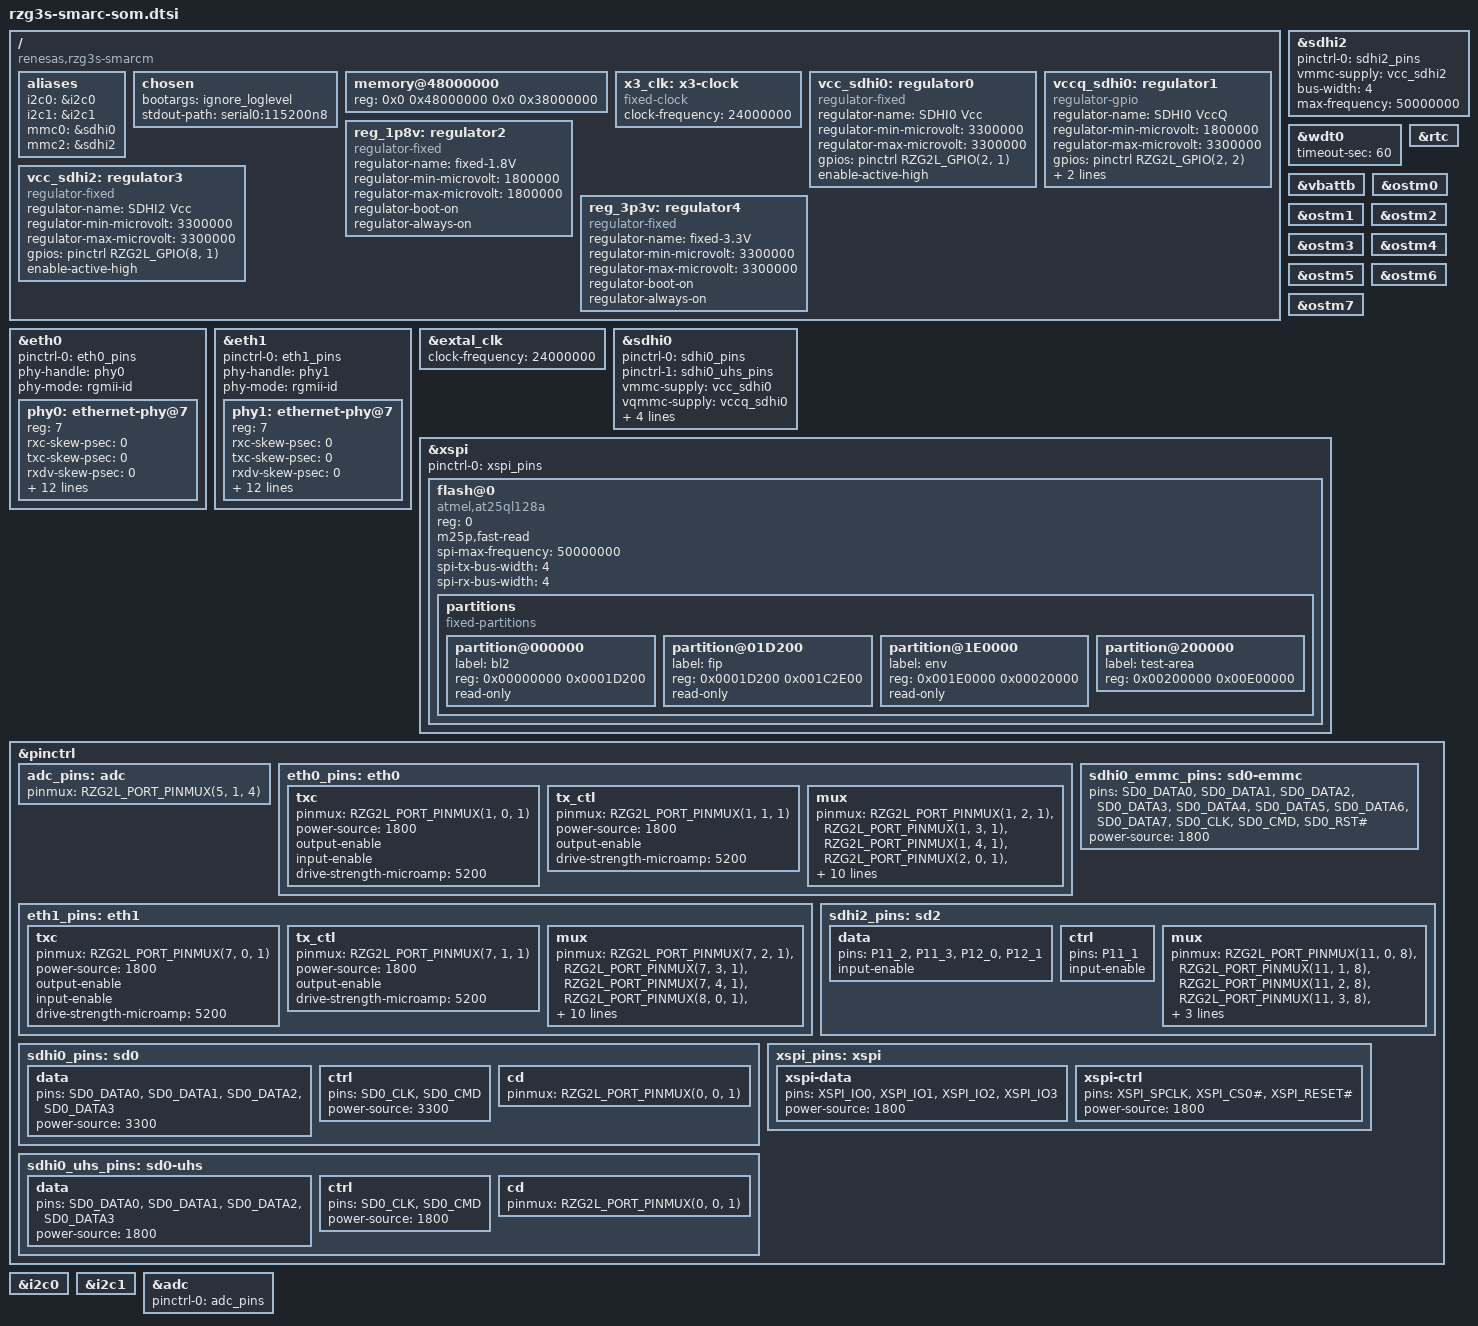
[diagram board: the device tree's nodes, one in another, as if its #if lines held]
// SPDX-License-Identifier: (GPL-2.0-only OR BSD-2-Clause)
/*
 * Device Tree Source for the R9A08G045S33 SMARC Carrier-II's SoM board.
 *
 * Copyright (C) 2023 Renesas Electronics Corp.
 */

#include <dt-bindings/gpio/gpio.h>
#include <dt-bindings/pinctrl/rzg2l-pinctrl.h>

/*
 * SSI-DA7212
 *
 * These commands are required when Playback/Capture
 *
 *	amixer -q cset name='Aux Switch' on
 *	amixer -q cset name='Mixin Left Aux Left Switch' on
 *	amixer -q cset name='Mixin Right Aux Right Switch' on
 *	amixer -q cset name='ADC Switch' on
 *	amixer -q cset name='Mixout Right Mixin Right Switch' off
 *	amixer -q cset name='Mixout Left Mixin Left Switch' off
 *	amixer -q cset name='Headphone Volume' 70%
 *	amixer -q cset name='Headphone Switch' on
 *	amixer -q cset name='Mixout Left DAC Left Switch' on
 *	amixer -q cset name='Mixout Right DAC Right Switch' on
 *	amixer -q cset name='DAC Left Source MUX' 'DAI Input Left'
 *	amixer -q cset name='DAC Right Source MUX' 'DAI Input Right'
 *	amixer -q sset 'Mic 1 Amp Source MUX' 'MIC_P'
 *	amixer -q sset 'Mic 2 Amp Source MUX' 'MIC_P'
 *	amixer -q sset 'Mixin Left Mic 1' on
 *	amixer -q sset 'Mixin Right Mic 2' on
 *	amixer -q sset 'Mic 1' 90% on
 *	amixer -q sset 'Mic 2' 90% on
 *	amixer -q sset 'Lineout' 80% on
 *	amixer -q set "Headphone" 100% on
 */

/ {
	compatible = "renesas,rzg3s-smarcm", "renesas,r9a08g045s33", "renesas,r9a08g045";

	aliases {
		i2c0 = &i2c0;
		i2c1 = &i2c1;
		mmc0 = &sdhi0;
#if SW_CONFIG3 == SW_OFF
		mmc2 = &sdhi2;
#else
		eth0 = &eth0;
		eth1 = &eth1;
#endif
	};

	chosen {
		bootargs = "ignore_loglevel";
		stdout-path = "serial0:115200n8";
	};

	memory@48000000 {
		device_type = "memory";
		/* First 128MB is reserved for secure area. */
		reg = <0x0 0x48000000 0x0 0x38000000>;
	};

	x3_clk: x3-clock {
		compatible = "fixed-clock";
		#clock-cells = <0>;
		clock-frequency = <24000000>;
	};

	vcc_sdhi0: regulator0 {
		compatible = "regulator-fixed";
		regulator-name = "SDHI0 Vcc";
		regulator-min-microvolt = <3300000>;
		regulator-max-microvolt = <3300000>;
		gpios = <&pinctrl RZG2L_GPIO(2, 1) GPIO_ACTIVE_HIGH>;
		enable-active-high;
	};

#if SW_CONFIG2 == SW_ON
	vccq_sdhi0: regulator1 {
		compatible = "regulator-gpio";
		regulator-name = "SDHI0 VccQ";
		regulator-min-microvolt = <1800000>;
		regulator-max-microvolt = <3300000>;
		gpios = <&pinctrl RZG2L_GPIO(2, 2) GPIO_ACTIVE_HIGH>;
		gpios-states = <1>;
		states = <3300000 1>, <1800000 0>;
	};
#endif

	reg_1p8v: regulator2 {
		compatible = "regulator-fixed";
		regulator-name = "fixed-1.8V";
		regulator-min-microvolt = <1800000>;
		regulator-max-microvolt = <1800000>;
		regulator-boot-on;
		regulator-always-on;
	};

	vcc_sdhi2: regulator3 {
		compatible = "regulator-fixed";
		regulator-name = "SDHI2 Vcc";
		regulator-min-microvolt = <3300000>;
		regulator-max-microvolt = <3300000>;
		gpios = <&pinctrl RZG2L_GPIO(8, 1) GPIO_ACTIVE_HIGH>;
		enable-active-high;
	};

	reg_3p3v: regulator4 {
		compatible = "regulator-fixed";
		regulator-name = "fixed-3.3V";
		regulator-min-microvolt = <3300000>;
		regulator-max-microvolt = <3300000>;
		regulator-boot-on;
		regulator-always-on;
	};
};

#if SW_CONFIG3 == SW_ON
&eth0 {
	pinctrl-0 = <&eth0_pins>;
	pinctrl-names = "default";
	phy-handle = <&phy0>;
	phy-mode = "rgmii-id";
	status = "okay";

	phy0: ethernet-phy@7 {
		reg = <7>;
		rxc-skew-psec = <0>;
		txc-skew-psec = <0>;
		rxdv-skew-psec = <0>;
		txen-skew-psec = <0>;
		rxd0-skew-psec = <0>;
		rxd1-skew-psec = <0>;
		rxd2-skew-psec = <0>;
		rxd3-skew-psec = <0>;
		txd0-skew-psec = <0>;
		txd1-skew-psec = <0>;
		txd2-skew-psec = <0>;
		txd3-skew-psec = <0>;

		interrupt-parent = <&pinctrl>;
		interrupts = <RZG2L_GPIO(12, 0) IRQ_TYPE_LEVEL_LOW>; /* RZ_IRQ0 */
	};
};

&eth1 {
	pinctrl-0 = <&eth1_pins>;
	pinctrl-names = "default";
	phy-handle = <&phy1>;
	phy-mode = "rgmii-id";
	status = "okay";

	phy1: ethernet-phy@7 {
		reg = <7>;
		rxc-skew-psec = <0>;
		txc-skew-psec = <0>;
		rxdv-skew-psec = <0>;
		txen-skew-psec = <0>;
		rxd0-skew-psec = <0>;
		rxd1-skew-psec = <0>;
		rxd2-skew-psec = <0>;
		rxd3-skew-psec = <0>;
		txd0-skew-psec = <0>;
		txd1-skew-psec = <0>;
		txd2-skew-psec = <0>;
		txd3-skew-psec = <0>;

		interrupt-parent = <&pinctrl>;
		interrupts = <RZG2L_GPIO(12, 1) IRQ_TYPE_LEVEL_LOW>; /* RZ_IRQ1 */
	};
};
#endif

&extal_clk {
	clock-frequency = <24000000>;
};

#if SW_CONFIG2 == SW_ON
/* SD0 slot */
&sdhi0 {
	pinctrl-0 = <&sdhi0_pins>;
	pinctrl-1 = <&sdhi0_uhs_pins>;
	pinctrl-names = "default", "state_uhs";
	vmmc-supply = <&vcc_sdhi0>;
	vqmmc-supply = <&vccq_sdhi0>;
	bus-width = <4>;
	sd-uhs-sdr50;
	sd-uhs-sdr104;
	max-frequency = <125000000>;
	status = "okay";
};
#else
/* eMMC */
&sdhi0 {
	pinctrl-0 = <&sdhi0_emmc_pins>;
	pinctrl-1 = <&sdhi0_emmc_pins>;
	pinctrl-names = "default", "state_uhs";
	vmmc-supply = <&vcc_sdhi0>;
	vqmmc-supply = <&reg_1p8v>;
	bus-width = <8>;
	mmc-hs200-1_8v;
	non-removable;
	fixed-emmc-driver-type = <1>;
	max-frequency = <125000000>;
	status = "okay";
};
#endif

#if SW_CONFIG3 == SW_OFF
&sdhi2 {
	pinctrl-0 = <&sdhi2_pins>;
	pinctrl-names = "default";
	vmmc-supply = <&vcc_sdhi2>;
	bus-width = <4>;
	max-frequency = <50000000>;
	status = "okay";
};
#endif

&wdt0 {
	status = "okay";
	timeout-sec = <60>;
};

&rtc {
	status = "okay";
};

&vbattb {
	status = "okay";
};

&ostm0 {
	status = "okay";
};

&ostm1 {
	status = "okay";
};

&ostm2 {
	status = "okay";
};

&ostm3 {
	status = "okay";
};

&ostm4 {
	status = "okay";
};

&ostm5 {
	status = "okay";
};

&ostm6 {
	status = "okay";
};

&ostm7 {
	status = "okay";
};

&xspi {
	pinctrl-0 = <&xspi_pins>;
	pinctrl-names = "default";

	status = "okay";

	flash@0 {
		compatible = "atmel,at25ql128a", "jedec,spi-nor";
		reg = <0>;
		m25p,fast-read;
		spi-max-frequency = <50000000>;
		spi-tx-bus-width = <4>;
		spi-rx-bus-width = <4>;

		partitions {
			compatible = "fixed-partitions";
			#address-cells = <1>;
			#size-cells = <1>;

			partition@000000 {
				label = "bl2";
				reg = <0x00000000 0x0001D200>;
				read-only;
			};
			partition@01D200 {
				label = "fip";
				reg = <0x0001D200 0x001C2E00>;
				read-only;
			};
			partition@1E0000 {
				label = "env";
				reg = <0x001E0000 0x00020000>;
				read-only;
			};
			partition@200000 {
				label = "test-area";
				reg = <0x00200000 0x00E00000>;
			};
		};
	};
};

&pinctrl {
	adc_pins: adc {
		pinmux = <RZG2L_PORT_PINMUX(5, 1, 4)>; /* ADC_TRG */
	};

#if SW_CONFIG3 == SW_ON
	eth0_pins: eth0 {
		txc {
			pinmux = <RZG2L_PORT_PINMUX(1, 0, 1)>;  /* ET0_TXC */
			power-source = <1800>;
			output-enable;
			input-enable;
			drive-strength-microamp = <5200>;
		};

		tx_ctl {
			pinmux = <RZG2L_PORT_PINMUX(1, 1, 1)>;  /* ET0_TX_CTL */
			power-source = <1800>;
			output-enable;
			drive-strength-microamp = <5200>;
		};

		mux {
			pinmux = <RZG2L_PORT_PINMUX(1, 2, 1)>,	/* ET0_TXD0 */
				 <RZG2L_PORT_PINMUX(1, 3, 1)>,	/* ET0_TXD1 */
				 <RZG2L_PORT_PINMUX(1, 4, 1)>,	/* ET0_TXD2 */
				 <RZG2L_PORT_PINMUX(2, 0, 1)>,	/* ET0_TXD3 */
				 <RZG2L_PORT_PINMUX(3, 0, 1)>,	/* ET0_RXC */
				 <RZG2L_PORT_PINMUX(3, 1, 1)>,	/* ET0_RX_CTL */
				 <RZG2L_PORT_PINMUX(3, 2, 1)>,	/* ET0_RXD0 */
				 <RZG2L_PORT_PINMUX(3, 3, 1)>,	/* ET0_RXD1 */
				 <RZG2L_PORT_PINMUX(4, 0, 1)>,	/* ET0_RXD2 */
				 <RZG2L_PORT_PINMUX(4, 1, 1)>,	/* ET0_RXD3 */
				 <RZG2L_PORT_PINMUX(4, 3, 1)>,	/* ET0_MDC */
				 <RZG2L_PORT_PINMUX(4, 4, 1)>,	/* ET0_MDIO */
				 <RZG2L_PORT_PINMUX(4, 5, 1)>;	/* ET0_LINKSTA */
			power-source = <1800>;
		};
	};

	eth1_pins: eth1 {
		txc {
			pinmux = <RZG2L_PORT_PINMUX(7, 0, 1)>;	/* ET1_TXC */
			power-source = <1800>;
			output-enable;
			input-enable;
			drive-strength-microamp = <5200>;
		};

		tx_ctl {
			pinmux = <RZG2L_PORT_PINMUX(7, 1, 1)>;	/* ET1_TX_CTL */
			power-source = <1800>;
			output-enable;
			drive-strength-microamp = <5200>;
		};

		mux {
			pinmux = <RZG2L_PORT_PINMUX(7, 2, 1)>,	/* ET1_TXD0 */
				 <RZG2L_PORT_PINMUX(7, 3, 1)>,	/* ET1_TXD1 */
				 <RZG2L_PORT_PINMUX(7, 4, 1)>,	/* ET1_TXD2 */
				 <RZG2L_PORT_PINMUX(8, 0, 1)>,	/* ET1_TXD3 */
				 <RZG2L_PORT_PINMUX(8, 4, 1)>,	/* ET1_RXC */
				 <RZG2L_PORT_PINMUX(9, 0, 1)>,	/* ET1_RX_CTL */
				 <RZG2L_PORT_PINMUX(9, 1, 1)>,	/* ET1_RXD0 */
				 <RZG2L_PORT_PINMUX(9, 2, 1)>,	/* ET1_RXD1 */
				 <RZG2L_PORT_PINMUX(9, 3, 1)>,	/* ET1_RXD2 */
				 <RZG2L_PORT_PINMUX(10, 0, 1)>,	/* ET1_RXD3 */
				 <RZG2L_PORT_PINMUX(10, 2, 1)>,	/* ET1_MDC */
				 <RZG2L_PORT_PINMUX(10, 3, 1)>,	/* ET1_MDIO */
				 <RZG2L_PORT_PINMUX(10, 4, 1)>;	/* ET1_LINKSTA */
			power-source = <1800>;
		};
	};
#endif

	sdhi0_pins: sd0 {
		data {
			pins = "SD0_DATA0", "SD0_DATA1", "SD0_DATA2", "SD0_DATA3";
			power-source = <3300>;
		};

		ctrl {
			pins = "SD0_CLK", "SD0_CMD";
			power-source = <3300>;
		};

		cd {
			pinmux = <RZG2L_PORT_PINMUX(0, 0, 1)>; /* SD0_CD */
		};
	};

	sdhi0_uhs_pins: sd0-uhs {
		data {
			pins = "SD0_DATA0", "SD0_DATA1", "SD0_DATA2", "SD0_DATA3";
			power-source = <1800>;
		};

		ctrl {
			pins = "SD0_CLK", "SD0_CMD";
			power-source = <1800>;
		};

		cd {
			pinmux = <RZG2L_PORT_PINMUX(0, 0, 1)>; /* SD0_CD */
		};
	};

	sdhi0_emmc_pins: sd0-emmc {
		pins = "SD0_DATA0", "SD0_DATA1", "SD0_DATA2", "SD0_DATA3",
		       "SD0_DATA4", "SD0_DATA5", "SD0_DATA6", "SD0_DATA7",
		       "SD0_CLK", "SD0_CMD", "SD0_RST#";
		power-source = <1800>;
	};

#if SW_CONFIG3 == SW_OFF
	sdhi2_pins: sd2 {
		data {
			pins = "P11_2", "P11_3", "P12_0", "P12_1";
			input-enable;
		};

		ctrl {
			pins = "P11_1";
			input-enable;
		};

		mux {
			pinmux = <RZG2L_PORT_PINMUX(11, 0, 8)>, /* SD2_CLK */
				 <RZG2L_PORT_PINMUX(11, 1, 8)>, /* SD2_CMD */
				 <RZG2L_PORT_PINMUX(11, 2, 8)>, /* SD2_DATA0 */
				 <RZG2L_PORT_PINMUX(11, 3, 8)>, /* SD2_DATA1 */
				 <RZG2L_PORT_PINMUX(12, 0, 8)>, /* SD2_DATA2 */
				 <RZG2L_PORT_PINMUX(12, 1, 8)>, /* SD2_DATA3 */
				 <RZG2L_PORT_PINMUX(14, 1, 7)>; /* SD2_CD# */
		};
	};
#endif

	xspi_pins: xspi {
		xspi-data {
			pins = "XSPI_IO0", "XSPI_IO1", "XSPI_IO2", "XSPI_IO3";
			power-source = <1800>;
		};

		xspi-ctrl {
			pins = "XSPI_SPCLK", "XSPI_CS0#", "XSPI_RESET#";
			power-source = <1800>;
		};
	};
};

&i2c0 {
	status = "okay";
};

&i2c1 {
	status = "okay";
};

&adc {
	pinctrl-0 = <&adc_pins>;
	pinctrl-names = "default";

	status = "okay";
};
